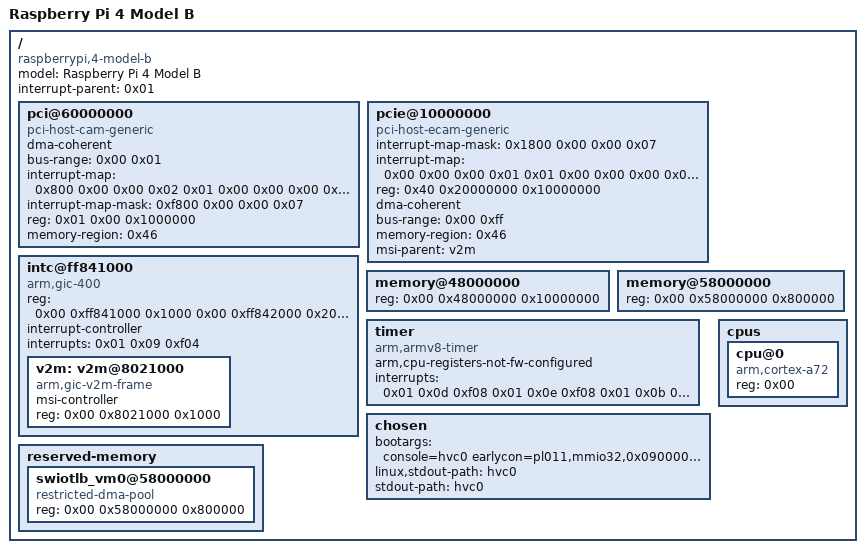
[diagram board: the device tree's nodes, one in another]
/* Example of a device tree with both CAmkES vPCI and QEMU vPCI.
 * Set UserVmDtb ON and compile dtb:
 *   $ dtc -I dts -O dtb -o user-vm.dtb dm-vpci-swiotlb.dts
*/
/dts-v1/;

/ {
	#address-cells = <0x02>;
	model = "Raspberry Pi 4 Model B";
	#size-cells = <0x01>;
	interrupt-parent = <0x01>;
	compatible = "raspberrypi,4-model-b\0brcm,bcm2711";

	pci@60000000 {
		#address-cells = <0x03>;
		dma-coherent;
		bus-range = <0x00 0x01>;
		interrupt-map = <0x800 0x00 0x00 0x02 0x01 0x00 0x00 0x00 0x29 0x04 0x1000 0x00 0x00 0x03 0x01 0x00 0x00 0x00 0x2a 0x04 0x1800 0x00 0x00 0x04 0x01 0x00 0x00 0x00 0x2b 0x04 0x2000 0x00 0x00 0x01 0x01 0x00 0x00 0x00 0x28 0x04>;
		#size-cells = <0x02>;
		device_type = "pci";
		interrupt-map-mask = <0xf800 0x00 0x00 0x07>;
		compatible = "pci-host-cam-generic";
		ranges = <0x1000000 0x00 0x00 0x01 0x1000000 0x00 0x10000 0x2000000 0x00 0x60000000 0x00 0x60000000 0x00 0x60000000>;
		#interrupt-cells = <0x01>;
		reg = <0x01 0x00 0x1000000>;
		/* use swiotlb */
		memory-region = <0x46>;
	};


	pcie@10000000 {
		interrupt-map-mask = <0x1800 0x00 0x00 0x07>;
		interrupt-map = <0x00 0x00 0x00 0x01 0x01 0x00 0x00 0x00 0x03 0x04 0x00 0x00 0x00 0x02 0x01 0x00 0x00 0x00 0x04 0x04 0x00 0x00 0x00 0x03 0x01 0x00 0x00 0x00 0x05 0x04 0x00 0x00 0x00 0x04 0x01 0x00 0x00 0x00 0x06 0x04 0x800 0x00 0x00 0x01 0x01 0x00 0x00 0x00 0x04 0x04 0x800 0x00 0x00 0x02 0x01 0x00 0x00 0x00 0x05 0x04 0x800 0x00 0x00 0x03 0x01 0x00 0x00 0x00 0x06 0x04 0x800 0x00 0x00 0x04 0x01 0x00 0x00 0x00 0x03 0x04 0x1000 0x00 0x00 0x01 0x01 0x00 0x00 0x00 0x05 0x04 0x1000 0x00 0x00 0x02 0x01 0x00 0x00 0x00 0x06 0x04 0x1000 0x00 0x00 0x03 0x01 0x00 0x00 0x00 0x03 0x04 0x1000 0x00 0x00 0x04 0x01 0x00 0x00 0x00 0x04 0x04 0x1800 0x00 0x00 0x01 0x01 0x00 0x00 0x00 0x06 0x04 0x1800 0x00 0x00 0x02 0x01 0x00 0x00 0x00 0x03 0x04 0x1800 0x00 0x00 0x03 0x01 0x00 0x00 0x00 0x04 0x04 0x1800 0x00 0x00 0x04 0x01 0x00 0x00 0x00 0x05 0x04>;
		#interrupt-cells = <0x01>;
		ranges = <0x1000000 0x00 0x00 0x00 0x3eff0000 0x00 0x10000 0x2000000 0x00 0x10000000 0x00 0x10000000 0x00 0x2eff0000 0x3000000 0x80 0x00 0x80 0x00 0x80 0x00>;
		reg = <0x40 0x20000000 0x10000000>;
		dma-coherent;
		bus-range = <0x00 0xff>;
		#size-cells = <0x02>;
		#address-cells = <0x03>;
		device_type = "pci";
		compatible = "pci-host-ecam-generic";
		/* use swiotlb */
		memory-region = <0x46>;
		msi-parent = <&v2m>;
	};

	intc@ff841000 {
		#address-cells = <0x02>;
		#size-cells = <0x01>;
		compatible = "arm,gic-400";
		ranges;
		#interrupt-cells = <0x03>;
		reg = <0x00 0xff841000 0x1000 0x00 0xff842000 0x2000 0x00 0xff844000 0x2000 0x00 0xff846000 0x2000>;
		phandle = <0x01>;
		interrupt-controller;
		interrupts = <0x01 0x09 0xf04>;

		v2m: v2m@8021000 {
			msi-controller;
			compatible = "arm,gic-v2m-frame";
			reg = <0x00 0x8021000 0x1000>;
		};
	};

	memory@48000000 {
		device_type = "memory";
		reg = <0x00 0x48000000 0x10000000>;
	};

	memory@58000000 {
		device_type = "memory";
		reg = <0x00 0x58000000 0x800000>;
	};

	timer {
		arm,cpu-registers-not-fw-configured;
		interrupts = <0x01 0x0d 0xf08 0x01 0x0e 0xf08 0x01 0x0b 0xf08 0x01 0x0a 0xf08>;
		compatible = "arm,armv8-timer";
	};

	chosen {
		bootargs = "console=hvc0 earlycon=pl011,mmio32,0x09000000 root=/dev/vda2 rw debug loglevel=8 initcall_blacklist=clk_disable_unused maxcpus=1";
		linux,stdout-path = "hvc0";
		stdout-path = "hvc0";
	};

	cpus {
		#address-cells = <0x01>;
		#size-cells = <0x00>;

		cpu@0 {
			device_type = "cpu";
			compatible = "arm,cortex-a72";
			reg = <0x00>;
		};
	};

	reserved-memory {
		#address-cells = <0x02>;
		#size-cells = <0x01>;
		ranges;
		phandle = <0x41>;

		swiotlb_vm0@58000000 {
			compatible = "restricted-dma-pool";
			reg = <0x00 0x58000000 0x800000>;
			phandle = <0x46>;
		};
	};
};
